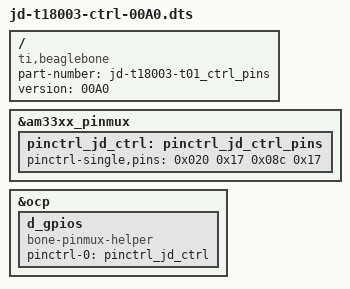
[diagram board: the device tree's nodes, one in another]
/dts-v1/;
/plugin/;

/ {
    	compatible = "ti,beaglebone", "ti,beaglebone-black";

	/* identification */
    	part-number = "jd-t18003-t01_ctrl_pins";
	version = "00A0";

	/******************************************/
	/* pinmuxing                              */
	/*                                        */
    	fragment@0 {
        	target = <&am33xx_pinmux>;
        	__overlay__ {
            		pinctrl_jd_ctrl: pinctrl_jd_ctrl_pins {
                		pinctrl-single,pins = <
                 			0x020 0x17 /* rs:  P8_19 = EHRPWM2A, OUTPUT_PULLUP  | MODE7 */
	                 		0x08c 0x17 /* reset:  P8_18 =gpio2[1] ,  OUTPUT_PULLUP | MODE7 */
             			>;
            		};
        	};
    	};

	/******************************************/
	/* GPIO pins                              */
	/*                                        */
	fragment@20 {
		target = <&ocp>;
		__overlay__ {
			#address-cells = <1>;
			#size-cells = <1>;
			d_gpios {
				compatible = "bone-pinmux-helper";
				pinctrl-names = "default";
				pinctrl-0 = <&pinctrl_jd_ctrl>;
				status = "okay";
			};
		};
	};
};

